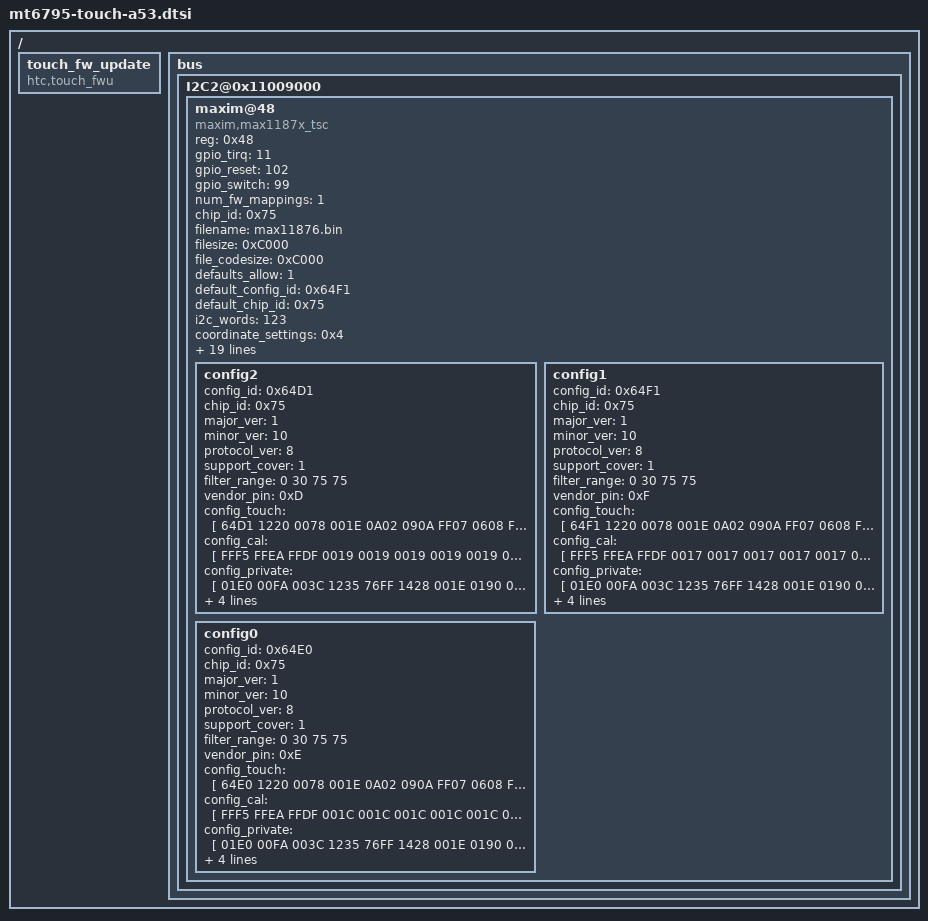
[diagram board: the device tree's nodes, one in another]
/{
	touch_fw_update {
		compatible = "htc,touch_fwu";
	};

	bus {
		I2C2@0x11009000 {
			maxim@48 {
				compatible = "maxim,max1187x_tsc";
				reg = <0x48>;
				gpio_tirq = <11>;
				gpio_reset = <102>;
				gpio_switch = <99>;
				num_fw_mappings = <1>;
				chip_id = <0x75>;
				filename = "max11876.bin";
				filesize = <0xC000>;
				file_codesize = <0xC000>;
				defaults_allow = <1>;
				default_config_id = <0x64F1>;
				default_chip_id = <0x75>;
				i2c_words = <123>;
				coordinate_settings = <0x4>;
				panel_min_x = <0>;
				panel_max_x = <1620>;
				panel_min_y = <0>;
				panel_max_y = <2880>;
				lcd_x = <1080>;
				lcd_y = <1920>;
				num_rows = <32>;
				num_cols = <18>;
				input_protocol = <1>;
				button_code0 = <0>;
				button_code1 = <0>;
				button_code2 = <0>;
				button_code3 = <0>;
				update_feature = <2>;
				tw_mask = <0xF>;
				report_mode = <2>;
				switch_invert;
				hall_block_touch_time = <1000>;
				retry_config_update_delay = <200>;

				config2 {
					config_id = <0x64D1>;
					chip_id = <0x75>;
					major_ver = <1>;
					minor_ver = <10>;
					protocol_ver = <8>;
					support_cover = <1>;
					filter_range = <0 30 75 75>;
					vendor_pin = <0xD>;
					config_touch = [
						64D1 1220 0078 001E 0A02 090A FF07 0608
						FF03 0502 01FF 0004 0B0F 0E10 0C11 12FF
						FF0D 13FF 14FF 1A16 FF17 181C 191D 1E1B
						151F 0100 0302 0504 0706 0908 0B0A 0D0C
						0F0E 1110 FFFF FFFF FFFF FFFF FFFF FFFF
						FFFF 0B3F 0653 0513 0001 0502 0B2C 0834
						03E8 05DC 0096 1900 0A06 FFFF FFFF FFFF
						FFFF 0014 FFFF FFFF FFFF FFFF FFFF FFFF
						2137
					];
					config_cal = [
						FFF5 FFEA FFDF 0019 0019 0019 0019 0019
						0019 0019 0019 0019 0019 0019 0019 0019
						0019 0019 0019 0019 0019 0019 0019 0019
						0019 0019 0019 0003 0003 0003 0003 0003
						0003 0003 0003 0003 0003 0003 0003 0003
						0003 0003 0003 0003 0003 0000 0000 0000
						0000 0000 0000 FFFF FF1E 010E 0104 0104
						0104 00FF 0109 0109 00FF 00FF 000A 0001
						0001 0002 0002 0003 0001 0001 0002 0002
						0003 0AAE
					];
					config_private = [
						01E0 00FA 003C 1235 76FF 1428 001E 0190
						0258 00AA 00FA 0018 04E2 003C 1414 AD32
						FEFE 14FF FDFD FFFF 00FF FF15 4E21 0783
						7864 5226 FFFF FFFF FFFF FFFF FFFF FFFF
						FFFF 9ECC
					];
					config_lin_x = [
						0031 361E 664E 917E B1A1 D1C1 F0E1 A25E
					];
					config_lin_y = [
						0035 3820 6850 9580 B5A5 D5C5 F5E5 B774
					];
				};

				config1 {
					config_id = <0x64F1>;
					chip_id = <0x75>;
					major_ver = <1>;
					minor_ver = <10>;
					protocol_ver = <8>;
					support_cover = <1>;
					filter_range = <0 30 75 75>;
					vendor_pin = <0xF>;
					config_touch = [
						64F1 1220 0078 001E 0A02 090A FF07 0608
						FF03 0502 01FF 0004 0B0F 0E10 0C11 12FF
						FF0D 13FF 14FF 1A16 FF17 181C 191D 1E1B
						151F 0100 0302 0504 0706 0908 0B0A 0D0C
						0F0E 1110 FFFF FFFF FFFF FFFF FFFF FFFF
						FFFF 0B3F 0653 0513 0001 0502 0B2C 0834
						03E8 05DC 0096 1900 0A06 FFFF FFFF FFFF
						FFFF 0014 FFFF FFFF FFFF FFFF FFFF FFFF
						2157
					];
					config_cal = [
						FFF5 FFEA FFDF 0017 0017 0017 0017 0017
						0017 0017 0017 0017 0017 0017 0017 0017
						0017 0017 0017 0017 0017 0017 0017 0017
						0017 0017 0017 0002 0002 0002 0002 0002
						0002 0002 0002 0002 0002 0002 0002 0002
						0002 0002 0002 0002 0002 0000 0000 0000
						0000 0000 0000 FFFF FF1E 010E 0104 0104
						0104 00FF 0109 0109 00FF 00FF 000A 0001
						0001 0002 0002 0003 0001 0001 0002 0002
						0003 0A6C
					];
					config_private = [
						01E0 00FA 003C 1235 76FF 1428 001E 0190
						0258 00AA 00FA 0018 04E2 003C 1414 AD32
						FCFC 14FE FDFD FFFF 00FF FF15 4E21 0783
						7864 5226 FFFF FFFF FFFF FFFF FFFF FFFF
						FFFF 9CC9
					];
					config_lin_x = [
						0031 361E 664E 917E B1A1 D1C1 F0E1 A25E
					];
					config_lin_y = [
						0035 3820 6850 9580 B5A5 D5C5 F5E5 B774
					];
				};

				config0 {
					config_id = <0x64E0>;
					chip_id = <0x75>;
					major_ver = <1>;
					minor_ver = <10>;
					protocol_ver = <8>;
					support_cover = <1>;
					filter_range = <0 30 75 75>;
					vendor_pin = <0xE>;
					config_touch = [
						64E0 1220 0078 001E 0A02 090A FF07 0608
						FF03 0502 01FF 0004 0B0F 0E10 0C11 12FF
						FF0D 13FF 14FF 1A16 FF17 181C 191D 1E1B
						151F 0100 0302 0504 0706 0908 0B0A 0D0C
						0F0E 1110 FFFF FFFF FFFF FFFF FFFF FFFF
						FFFF 0B3F 0653 0513 0001 0A02 07BC 0A8C
						03E8 05DC 0190 1900 0A06 FFFF FFFF FFFF
						FFFF 0014 FFFF FFFF FFFF FFFF FFFF FFFF
						2628
					];
					config_cal = [
						FFF5 FFEA FFDF 001C 001C 001C 001C 001C
						001C 001C 001C 001C 001C 001C 001C 001C
						001C 001C 001C 001C 001C 001C 001C 001C
						001C 001C 001C 0004 0004 0004 0004 0004
						0004 0004 0004 0004 0004 0004 0004 0004
						0004 0004 0004 0004 0004 0000 0000 0000
						0000 0000 0000 FFFF FF1E 00FF 0104 0104
						0104 00FF 0109 0109 00FF 00FF 000A 0001
						0001 0002 0002 0003 0001 0001 0002 0002
						0003 0AF9
					];
					config_private = [
						01E0 00FA 003C 1235 76FF 1428 001E 0190
						0258 00AA 00FA 0018 04E2 003C 1414 B232
						FDFC 14FF FEFE FFFF 00FF FF15 4E21 0783
						7864 5226 FFFF FFFF FFFF FFFF FFFF FFFF
						FFFF A3CB
					];
					config_lin_x = [
						0031 361E 664E 917E B1A1 D1C1 F0E1 A25E
					];
					config_lin_y = [
						0035 3820 6850 9580 B5A5 D5C5 F5E5 B774
					];
				};
			};
		};
	};
};
